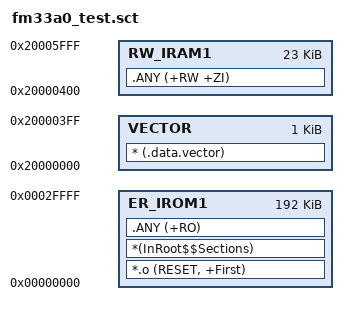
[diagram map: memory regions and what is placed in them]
; *************************************************************
; *** Scatter-Loading Description File generated by uVision ***
; *************************************************************

LR_IROM1 0x00000000 0x00030000  {    ; load region size_region
  ER_IROM1 0x00000000 0x00030000  {  ; load address = execution address
   *.o (RESET, +First)
   *(InRoot$$Sections)
   .ANY (+RO)
  }
  VECTOR 0x20000000 0x400  {    ; Vector
        * (.data.vector)
  }
  RW_IRAM1 0x20000400 0x00005c00  {  ; RW data
   .ANY (+RW +ZI)
  }
}

